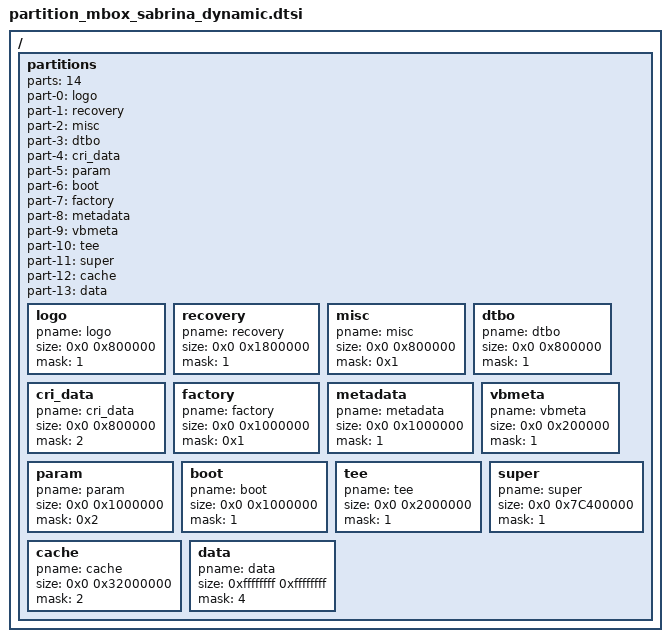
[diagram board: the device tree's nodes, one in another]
// SPDX-License-Identifier: (GPL-2.0+ OR MIT)
/*
 * Copyright (c) 2019 Amlogic, Inc. All rights reserved.
 *
 * partitionName,startsddr,size,partitionGap,attr
 * ab don't need cache, but dts part will add 8M for it
 * mask_flag, 0~7 bit for emmc/nand, bit 8 for dts gap
 * bit 0-3 is for Nand
 *
 * bit 4 and above are used only for GPT-format partition table.
 *
 * bit 4 is for EMMC. If set to 1, when burning the entire package,
            this partition will not be erased;
 * bit 5-7 is reserved and not useful now
 * bit 12 for file system, 0: ext4, 1: f2fs
 * bit 13 for backup gpt addr, 0: default,
 * 1: save backup gpt in the partition gap before current partition
 * for default gpt:
 *  LBA0               ----  Protective MBR
 *  LBA1               ----  Primary GPT Header
 *  LBA 2~33           ----  Entry
 *  LBA 34 ~ max-34    ----  partitions
 *  LBA max-33 ~ max-2 ----  Backup Entry
 *  LBA max-1          ----  Backup GPT Header
 *  for alternate gpt:
 *  LBA0               ----  Protective MBR
 *  LBA1               ----  Primary GPT Header
 *  LBA 2~33           ----  Entry
 *  LBA 34 ~ A         ----  partitions
 *  LBA gap before A-X ----  Backup Entry + Backup GPT Header
 *  LBA x ~ B          ----  choice partition
 *  LBA B + gap ~ max  ----  partitions
 */

#include "firmware_avb_sabrina.dtsi"

/ {
    partitions: partitions{
		parts = <14>;
		part-0 = <&logo>;
		part-1 = <&recovery>;
		part-2 = <&misc>;
		part-3 = <&dtbo>;
		part-4 = <&cri_data>;
		part-5 = <&param>;
		part-6 = <&boot>;
		part-7 = <&factory>;
		part-8 = <&metadata>;
		part-9 = <&vbmeta>;
		part-10 = <&tee>;
		part-11 = <&super>;
		part-12 = <&cache>;
		part-13 = <&data>;

		logo:logo{
			pname = "logo";
			size = <0x0 0x800000>;  /* 8 MiB */
			mask = <1>;
		};
		recovery:recovery{
			pname = "recovery";
			size = <0x0 0x1800000>; /* 24 MiB */
			mask = <1>;
		};
		misc:misc{
			pname = "misc";
			size = <0x0 0x800000>;  /* 8 MiB */
			mask = <0x1>;
		};
		dtbo:dtbo{
			pname = "dtbo";
			size = <0x0 0x800000>;  /* 8 MiB */
			mask = <1>;
		};
		cri_data:cri_data
		{
			pname = "cri_data";
			size = <0x0 0x800000>;  /* 8 MiB */
			mask = <2>;
		};
		factory:factory{
			pname = "factory";
			size = <0x0 0x1000000>; /* 16 MiB */
			mask = <0x1>;
		};
		metadata:metadata{
			pname = "metadata";
			size = <0x0 0x1000000>; /* 16 MiB */
			mask = <1>;
		};
		vbmeta:vbmeta{
			pname = "vbmeta";
			size = <0x0 0x200000>;  /* 2 MiB */
			mask = <1>;
		};
		param:param{
			pname = "param";
			size = <0x0 0x1000000>; /* 16 MiB */
			mask = <0x2>;
		};
		boot:boot
		{
			pname = "boot";
			size = <0x0 0x1000000>; /* 16 MiB */
			mask = <1>;
		};
		tee:tee{
			pname = "tee";
			size = <0x0 0x2000000>; /* 32 MiB */
			mask = <1>;
		};
		super:super
		{
			pname = "super";
			size = <0x0 0x7C400000>;    /* 1988 MiB */
			mask = <1>;
		};
		cache:cache
		{
			pname = "cache";
			size = <0x0 0x32000000>;    /* 800 MiB */
			mask = <2>;
		};
		data:data
		{
			pname = "data";
			size = <0xffffffff 0xffffffff>; /* rest of the disk */
			mask = <4>;
		};
	};
};/* end of / */
